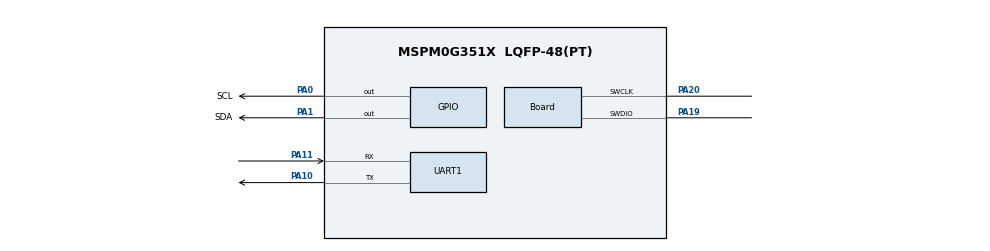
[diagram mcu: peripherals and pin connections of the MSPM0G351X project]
/**
 * @cliArgs --device "MSPM0G351X" --part "Default" --package "LQFP-48(PT)" --product "mspm0_sdk@2.02.00.05"
 * @versions {"tool":"1.21.1+3772"}
 */

/**
 * Import the modules used in this configuration.
 */
const GPIO    = scripting.addModule("/ti/driverlib/GPIO", {}, false);
const GPIO1   = GPIO.addInstance();
const SYSCTL  = scripting.addModule("/ti/driverlib/SYSCTL");
const SYSTICK = scripting.addModule("/ti/driverlib/SYSTICK");
const UART    = scripting.addModule("/ti/driverlib/UART", {}, false);
const UART1   = UART.addInstance();

/**
 * Write custom configuration values to the imported modules.
 */
const gate7  = system.clockTree["MFCLKGATE"];
gate7.enable = true;

GPIO1.$name                          = "I2C";
GPIO1.port                           = "PORTA";
GPIO1.associatedPins.create(2);
GPIO1.associatedPins[0].$name        = "SCL";
GPIO1.associatedPins[0].initialValue = "SET";
GPIO1.associatedPins[0].ioStructure  = "OD";
GPIO1.associatedPins[0].assignedPin  = "0";
GPIO1.associatedPins[0].pin.$assign  = "PA0";
GPIO1.associatedPins[1].$name        = "SDA";
GPIO1.associatedPins[1].initialValue = "SET";
GPIO1.associatedPins[1].ioStructure  = "OD";
GPIO1.associatedPins[1].assignedPin  = "1";
GPIO1.associatedPins[1].pin.$assign  = "PA1";

const Board                       = scripting.addModule("/ti/driverlib/Board", {}, false);
Board.peripheral.$assign          = "DEBUGSS";
Board.peripheral.swclkPin.$assign = "PA20";
Board.peripheral.swdioPin.$assign = "PA19";

SYSCTL.forceDefaultClkConfig = true;
SYSCTL.clockTreeEn           = true;

SYSTICK.periodEnable      = true;
SYSTICK.systickEnable     = true;
SYSTICK.interruptPriority = "0";
SYSTICK.period            = 32;

UART1.$name                    = "UART_0";
UART1.uartClkSrc               = "MFCLK";
UART1.enabledInterrupts        = ["RX"];
UART1.peripheral.$assign       = "UART0";
UART1.peripheral.rxPin.$assign = "PA11";
UART1.peripheral.txPin.$assign = "PA10";
UART1.txPinConfig.$name        = "ti_driverlib_gpio_GPIOPinGeneric0";
UART1.rxPinConfig.$name        = "ti_driverlib_gpio_GPIOPinGeneric1";

const ProjectConfig              = scripting.addModule("/ti/project_config/ProjectConfig", {}, false);
ProjectConfig.migrationCondition = true;
